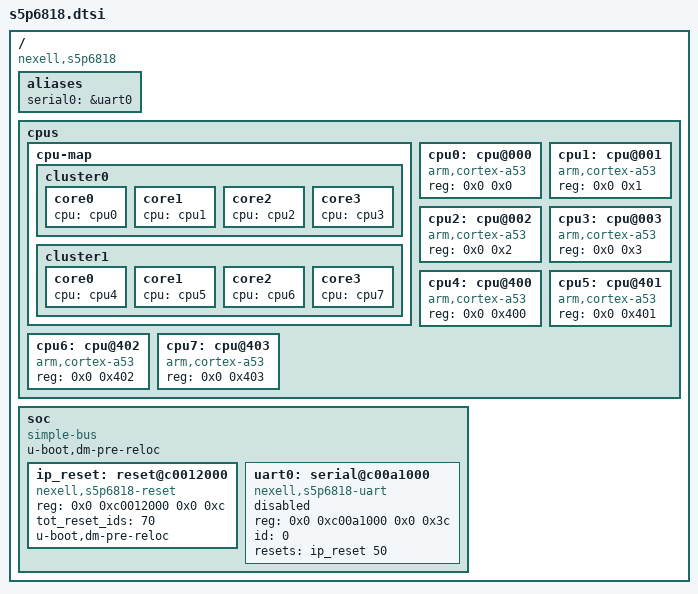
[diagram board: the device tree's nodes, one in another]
#include "skeleton64.dtsi"

/ {
	compatible = "nexell,s5p6818";
	
	aliases {
		serial0 = &uart0;
	};
	
	cpus {
		#address-cells = <2>;
		#size-cells = <0>;
		
		cpu-map {
			cluster0 {
				core0 {
					cpu = <&cpu0>;
				};
				core1 {
					cpu = <&cpu1>;
				};
				core2 {
					cpu = <&cpu2>;
				};
				core3 {
					cpu = <&cpu3>;
				};
			};
			cluster1 {
				core0 {
					cpu = <&cpu4>;
				};
				core1 {
					cpu = <&cpu5>;
				};
				core2 {
					cpu = <&cpu6>;
				};
				core3 {
					cpu = <&cpu7>;
				};
			};
		};
		
		cpu0: cpu@000 {
			compatible = "arm,cortex-a53", "arm,armv8";
			device_type = "cpu";
			reg = <0x0 0x0>;
			// enable-method = "psci";
		};
		
		cpu1: cpu@001 {
			compatible = "arm,cortex-a53", "arm,armv8";
			device_type = "cpu";
			reg = <0x0 0x1>;
			// enable-method = "psci";
		};
		
		cpu2: cpu@002 {
			compatible = "arm,cortex-a53", "arm,armv8";
			device_type = "cpu";
			reg = <0x0 0x2>;
			// enable-method = "psci";
		};
		
		cpu3: cpu@003 {
			compatible = "arm,cortex-a53", "arm,armv8";
			device_type = "cpu";
			reg = <0x0 0x3>;
			// enable-method = "psci";
		};
		
		cpu4: cpu@400 {
			compatible = "arm,cortex-a53", "arm,armv8";
			device_type = "cpu";
			reg = <0x0 0x400>;
			// enable-method = "psci";
		};
		
		cpu5: cpu@401 {
			compatible = "arm,cortex-a53", "arm,armv8";
			device_type = "cpu";
			reg = <0x0 0x401>;
			// enable-method = "psci";
		};
		
		cpu6: cpu@402 {
			compatible = "arm,cortex-a53", "arm,armv8";
			device_type = "cpu";
			reg = <0x0 0x402>;
			// enable-method = "psci";
		};
		
		cpu7: cpu@403 {
			compatible = "arm,cortex-a53", "arm,armv8";
			device_type = "cpu";
			reg = <0x0 0x403>;
			// enable-method = "psci";
		};
	};
	
	soc {
		#address-cells = <2>;
		#size-cells = <2>;
		compatible = "simple-bus";
		status = "okay";
		u-boot,dm-pre-reloc;
		ranges;
		
		ip_reset: reset@c0012000 {
			#reset-cells = <1>;
			compatible = "nexell,s5p6818-reset";
			reg = <0x0 0xc0012000 0x0 0xc>;
			tot_reset_ids = <70>;
			status = "okay";
			u-boot,dm-pre-reloc;
		};
		
		uart0: serial@c00a1000 {
			compatible = "nexell,s5p6818-uart";
			reg = <0x0 0xc00a1000 0x0 0x3c>;
			id = <0>;
			resets = <&ip_reset 50>;
			status = "disabled";
		};
	};
};

